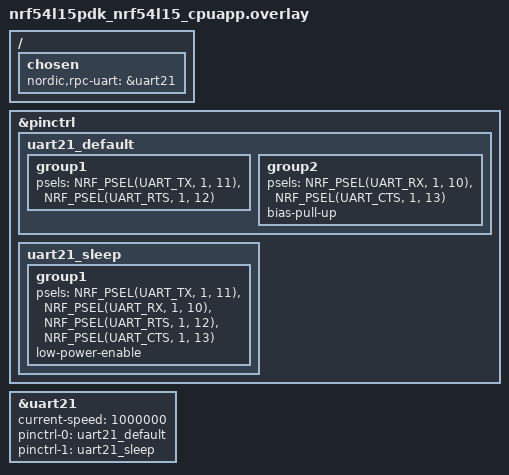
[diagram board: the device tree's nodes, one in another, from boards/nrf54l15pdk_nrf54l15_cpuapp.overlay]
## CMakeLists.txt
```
#
# Copyright (c) 2024 Nordic Semiconductor ASA
#
# SPDX-License-Identifier: LicenseRef-Nordic-5-Clause
#
cmake_minimum_required(VERSION 3.20.0)

find_package(Zephyr REQUIRED HINTS $ENV{ZEPHYR_BASE})

project(protocols_serialization_server)

# NORDIC SDK APP START
target_sources(app PRIVATE src/main.c)
# NORDIC SDK APP END

# Link OpenThread CLI even though OPENTHREAD_SHELL is not selected
if(CONFIG_OPENTHREAD_RPC)
zephyr_link_libraries(openthread-cli-ftd)
endif()
```

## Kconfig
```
#
# Copyright (c) 2024 Nordic Semiconductor ASA
#
# SPDX-License-Identifier: LicenseRef-Nordic-5-Clause
#

menu "Protocols serialization server"

choice LOG_MODE
	default LOG_MODE_DEFERRED
endchoice

config LOG_BUFFER_SIZE
	default 8192

config LOG_FUNC_NAME_PREFIX_DBG
	default n

config LOG_BACKEND_RTT
	default n

config LOG_BACKEND_UART
	default n

module = NRF_PS_SERVER
module-str = nrf_ps_server
source "${ZEPHYR_BASE}/subsys/logging/Kconfig.template.log_config"

endmenu # "Protocols serialization server"

menu "Zephyr Kernel"
source "Kconfig.zephyr"
endmenu
```

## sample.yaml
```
sample:
  name: Protocols serialization server application
  description: Demonstrates serialization of BLE and OpenThread API using nRF RPC
tests:
  applications.protocols_serialization.rpc_ble:
    build_only: true
    platform_allow: >
      nrf52840dk/nrf52840
      nrf54l15pdk/nrf54l15/cpuapp
    tags: ci_build ci_applications_protocols_serialization
    extra_args: >
      SNIPPET="ble"
    integration_platforms:
      - nrf52840dk/nrf52840
      - nrf54l15pdk/nrf54l15/cpuapp
  applications.protocols_serialization.rpc_ot:
    build_only: true
    platform_allow: >
      nrf52840dk/nrf52840
      nrf54l15pdk/nrf54l15/cpuapp
    tags: ci_build ci_applications_protocols_serialization
    extra_args: >
      SNIPPET="openthread"
    integration_platforms:
      - nrf52840dk/nrf52840
      - nrf54l15pdk/nrf54l15/cpuapp
  applications.protocols_serialization.rpc:
    build_only: true
    platform_allow: >
      nrf52840dk/nrf52840
      nrf54l15pdk/nrf54l15/cpuapp
    tags: ci_build ci_applications_protocols_serialization
    extra_args: >
      SNIPPET="ble;openthread;debug;coex;log_rpc"
    integration_platforms:
      - nrf52840dk/nrf52840
      - nrf54l15pdk/nrf54l15/cpuapp
```

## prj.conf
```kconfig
#
# Copyright (c) 2024 Nordic Semiconductor
#
# SPDX-License-Identifier: LicenseRef-Nordic-5-Clause
#
CONFIG_HEAP_MEM_POOL_SIZE=4096

CONFIG_NRF_RPC=y
CONFIG_NRF_RPC_CBOR=y
CONFIG_NRF_RPC_ZCBOR_BACKUPS=1
CONFIG_NRF_RPC_THREAD_STACK_SIZE=4096
CONFIG_NRF_RPC_GROUP_INIT_WAIT_TIME=-1
CONFIG_NRF_RPC_UART_TRANSPORT=y

CONFIG_UART_LINE_CTRL=y
CONFIG_UART_INTERRUPT_DRIVEN=y
```

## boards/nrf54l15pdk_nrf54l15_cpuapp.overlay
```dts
/* Copyright (c) 2024 Nordic Semiconductor ASA
 *
 * SPDX-License-Identifier: LicenseRef-Nordic-5-Clause
 */

 / {
	chosen {
		nordic,rpc-uart = &uart21;
	};
};

&pinctrl {
	uart21_default: uart21_default {
		group1 {
			psels = <NRF_PSEL(UART_TX, 1, 11)>,
				<NRF_PSEL(UART_RTS, 1, 12)>;
		};
		group2 {
			psels = <NRF_PSEL(UART_RX, 1, 10)>,
				<NRF_PSEL(UART_CTS, 1, 13)>;
			bias-pull-up;
		};
	};

	uart21_sleep: uart21_sleep {
		group1 {
			psels = <NRF_PSEL(UART_TX, 1, 11)>,
				<NRF_PSEL(UART_RX, 1, 10)>,
				<NRF_PSEL(UART_RTS, 1, 12)>,
				<NRF_PSEL(UART_CTS, 1, 13)>;
			low-power-enable;
		};
	};

};

&uart21 {
	status = "okay";
	current-speed = <1000000>;
	pinctrl-0 = <&uart21_default>;
	pinctrl-1 = <&uart21_sleep>;
	pinctrl-names = "default", "sleep";
};
```

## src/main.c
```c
/*
 * Copyright (c) 2024 Nordic Semiconductor ASA
 *
 * SPDX-License-Identifier: LicenseRef-Nordic-5-Clause
 */

#include <zephyr/logging/log.h>

#include <nrf_rpc.h>

LOG_MODULE_REGISTER(nrf_ps_server, CONFIG_NRF_PS_SERVER_LOG_LEVEL);

static void err_handler(const struct nrf_rpc_err_report *report)
{
	LOG_ERR("nRF RPC error %d ocurred. See nRF RPC logs for more details", report->code);
}

int main(void)
{
	int ret;

	LOG_INF("Initializing RPC server");

	ret = nrf_rpc_init(err_handler);

	if (ret != 0) {
		LOG_ERR("RPC init failed");
	}

	LOG_INF("RPC server ready");

	return 0;
}
```
